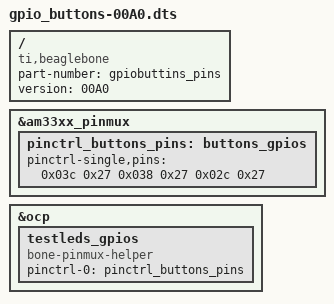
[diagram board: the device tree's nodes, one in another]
/dts-v1/;
/plugin/;

/ {
    	compatible = "ti,beaglebone", "ti,beaglebone-black";

	/* identification */
    	part-number = "gpiobuttins_pins";
	version = "00A0";

    	fragment@0 {
        	target = <&am33xx_pinmux>;
        	__overlay__ {
            		pinctrl_buttons_pins: buttons_gpios {
                		pinctrl-single,pins = <
	                 		0x03c 0x27 /* P8_15 = gpio1[15] */
					0x038 0x27 /* p8_16 = gpio1[14] */
					0x02c 0x27 /* p8_17 = gpio0[27] */
             			>;
            		};
        	};
    	};

	fragment@1 {
		target = <&ocp>;
		__overlay__ {
			#address-cells = <1>;
			#size-cells = <1>;
			testleds_gpios {
				compatible = "bone-pinmux-helper";
				pinctrl-names = "default";
				pinctrl-0 = <&pinctrl_buttons_pins>;
				status = "okay";
			};
		};
	};

};

